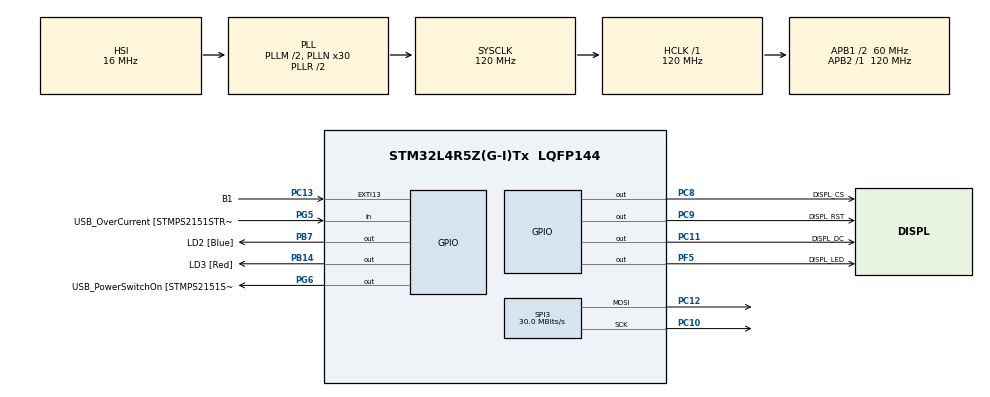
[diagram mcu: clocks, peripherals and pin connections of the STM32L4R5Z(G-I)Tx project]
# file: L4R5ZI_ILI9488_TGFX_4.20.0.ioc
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Dma.Request0=SPI3_TX
Dma.SPI3_TX.0.Direction=DMA_MEMORY_TO_PERIPH
Dma.SPI3_TX.0.EventEnable=DISABLE
Dma.SPI3_TX.0.Instance=DMA1_Channel1
Dma.SPI3_TX.0.MemDataAlignment=DMA_MDATAALIGN_BYTE
Dma.SPI3_TX.0.MemInc=DMA_MINC_ENABLE
Dma.SPI3_TX.0.Mode=DMA_NORMAL
Dma.SPI3_TX.0.PeriphDataAlignment=DMA_PDATAALIGN_BYTE
Dma.SPI3_TX.0.PeriphInc=DMA_PINC_DISABLE
Dma.SPI3_TX.0.Polarity=HAL_DMAMUX_REQUEST_GEN_RISING
Dma.SPI3_TX.0.Priority=DMA_PRIORITY_LOW
Dma.SPI3_TX.0.RequestNumber=1
Dma.SPI3_TX.0.SignalID=NONE
Dma.SPI3_TX.0.SyncEnable=DISABLE
Dma.SPI3_TX.0.SyncPolarity=HAL_DMAMUX_SYNC_NO_EVENT
Dma.SPI3_TX.0.SyncRequestNumber=1
Dma.SPI3_TX.0.SyncSignalID=NONE
Mcu.Family=STM32L4
Mcu.Name=STM32L4R5Z(G-I)Tx
Mcu.Package=LQFP144
NVIC.DMA1_Channel1_IRQn=true\:0\:0\:false\:false\:true\:false\:true\:true
NVIC.PriorityGroup=NVIC_PRIORITYGROUP_4
NVIC.SPI3_IRQn=true\:0\:0\:false\:false\:true\:true\:true\:true
NVIC.TIM3_IRQn=true\:0\:0\:false\:false\:true\:true\:true\:true
PA10.GPIO_Label=USB_ID
PA10.Signal=USB_OTG_FS_ID
PA11.GPIO_Label=USB_DM
PA11.Signal=USB_OTG_FS_DM
PA12.GPIO_Label=USB_DP
PA12.Signal=USB_OTG_FS_DP
PA13\ (JTMS/SWDIO).GPIO_Label=TMS
PA13\ (JTMS/SWDIO).Mode=Trace_Asynchronous_SW
PA13\ (JTMS/SWDIO).Signal=SYS_JTMS-SWDIO
PA14\ (JTCK/SWCLK).GPIO_Label=TCK
PA14\ (JTCK/SWCLK).Mode=Trace_Asynchronous_SW
PA14\ (JTCK/SWCLK).Signal=SYS_JTCK-SWCLK
PA8.GPIO_Label=USB_SOF [TP1]
PA8.Signal=USB_OTG_FS_SOF
PA9.GPIO_Label=USB_VBUS
PA9.Signal=USB_OTG_FS_VBUS
PB14.GPIO_Label=LD3 [Red]
PB14.Signal=GPIO_Output
PB3\ (JTDO/TRACESWO).GPIO_Label=SWO
PB3\ (JTDO/TRACESWO).Mode=Trace_Asynchronous_SW
PB3\ (JTDO/TRACESWO).Signal=SYS_JTDO-SWO
PB7.GPIO_Label=LD2 [Blue]
PB7.Signal=GPIO_Output
PC10.Mode=TX_Only_Simplex_Unidirect_Master
PC10.Signal=SPI3_SCK
PC11.GPIO_Label=DISPL_DC
PC11.GPIO_Speed=GPIO_SPEED_FREQ_HIGH
PC11.Signal=GPIO_Output
PC12.Mode=TX_Only_Simplex_Unidirect_Master
PC12.Signal=SPI3_MOSI
PC13.GPIO_Label=B1
PC13.Signal=GPXTI13
PC14-OSC32_IN\ (PC14).Mode=LSE-External-Oscillator
PC14-OSC32_IN\ (PC14).Signal=RCC_OSC32_IN
PC15-OSC32_OUT\ (PC15).Mode=LSE-External-Oscillator
PC15-OSC32_OUT\ (PC15).Signal=RCC_OSC32_OUT
PC8.GPIO_Label=DISPL_CS
PC8.GPIO_Speed=GPIO_SPEED_FREQ_HIGH
PC8.Signal=GPIO_Output
PC9.GPIO_Label=DISPL_RST
PC9.GPIO_Speed=GPIO_SPEED_FREQ_HIGH
PC9.Signal=GPIO_Output
PD8.GPIO_Label=STLK_RX [STM32F103CBT6_PA3]
PD8.Signal=USART3_TX
PD9.GPIO_Label=STLK_TX [STM32F103CBT6_PA2]
PD9.Signal=USART3_RX
PF5.GPIO_Label=DISPL_LED
PF5.Signal=GPIO_Output
PG5.GPIO_Label=USB_OverCurrent [STMPS2151STR_FAULT]
PG5.Signal=GPIO_Input
PG6.GPIO_Label=USB_PowerSwitchOn [STMPS2151STR_EN]
PG6.Signal=GPIO_Output
PG7.GPIO_Label=STLINK_TX
PG7.Signal=LPUART1_TX
PG8.GPIO_Label=STLINK_RX
PG8.Signal=LPUART1_RX
PH0-OSC_IN\ (PH0).Signal=RCC_OSC_IN
PH1-OSC_OUT\ (PH1).Signal=RCC_OSC_OUT
ProjectManager.HeapSize=0x200
ProjectManager.StackSize=0x400
ProjectManager.TargetToolchain=STM32CubeIDE
RCC.48MHZClocksFreq_Value=24000000
RCC.ADCFreq_Value=96000000
RCC.AHBFreq_Value=120000000
RCC.APB1CLKDivider=RCC_HCLK_DIV2
RCC.APB1Freq_Value=60000000
RCC.APB1TimFreq_Value=120000000
RCC.APB2Freq_Value=120000000
RCC.APB2TimFreq_Value=120000000
RCC.CK48CLockSelection=RCC_USBCLKSOURCE_HSI48
RCC.CortexFreq_Value=120000000
RCC.HCLKFreq_Value=120000000
RCC.HSE_VALUE=8000000
RCC.HSI48_VALUE=48000000
RCC.HSI_VALUE=16000000
RCC.MSI_VALUE=4000000
RCC.PLLM1=2
RCC.PLLMUL=RCC_PLL_MUL9
RCC.PLLN=30
RCC.PLLSAI1N=12
RCC.PLLSourceVirtual=RCC_PLLSOURCE_HSI
RCC.PRESCALERUSB=RCC_USBCLKSOURCE_PLL_DIV1_5
RCC.SYSCLKFreq_VALUE=120000000
RCC.SYSCLKSource=RCC_SYSCLKSOURCE_PLLCLK
RCC.SYSCLKSourceVirtual=RCC_SYSCLKSOURCE_PLLCLK
RCC.USBFreq_Value=48000000
RCC.VCOOutputFreq_Value=240000000
SPI3.BaudRatePrescaler=SPI_BAUDRATEPRESCALER_2
SPI3.CalculateBaudRate=30.0 MBits/s
SPI3.DataSize=SPI_DATASIZE_8BIT
SPI3.Direction=SPI_DIRECTION_2LINES
SPI3.Mode=SPI_MODE_MASTER
SPI3.VirtualType=VM_MASTER
STMicroelectronics.X-CUBE-TOUCHGFX.4.20.0.ApplicationCcGraphicsJjApplication=TouchGFXOoGenerator
STMicroelectronics.X-CUBE-TOUCHGFX.4.20.0.tgfx_block_size=27648
STMicroelectronics.X-CUBE-TOUCHGFX.4.20.0.tgfx_buffering_strategy=Partial
STMicroelectronics.X-CUBE-TOUCHGFX.4.20.0.tgfx_custom_height=480
STMicroelectronics.X-CUBE-TOUCHGFX.4.20.0.tgfx_custom_width=320
STMicroelectronics.X-CUBE-TOUCHGFX.4.20.0_IsPackSelfContextualization=true
TIM3.Period=50000-1
TIM3.Prescaler=120-1
VP_CRC_VS_CRC.Mode=CRC_Activate
VP_STMicroelectronics.X-CUBE-TOUCHGFX_VS_GraphicsJjApplication_4.20.0.Mode=GraphicsJjApplication
VP_TIM3_VS_ClockSourceINT.Mode=Internal
board=NUCLEO-L4R5ZI

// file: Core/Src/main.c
/* USER CODE BEGIN Header */
/**
  ******************************************************************************
  * @file           : main.c
  * @brief          : Main program body
  ******************************************************************************
  * @attention
  *
  * Copyright (c) 2024 STMicroelectronics.
  * All rights reserved.
  *
  * This software is licensed under terms that can be found in the LICENSE file
  * in the root directory of this software component.
  * If no LICENSE file comes with this software, it is provided AS-IS.
  *
  ******************************************************************************
  */
/* USER CODE END Header */
#include "main.h"
#include "app_touchgfx.h"

CRC_HandleTypeDef hcrc;

SPI_HandleTypeDef hspi3;
DMA_HandleTypeDef hdma_spi3_tx;

TIM_HandleTypeDef htim3;

void SystemClock_Config(void);
static void MX_GPIO_Init(void);
static void MX_DMA_Init(void);
static void MX_TIM3_Init(void);
static void MX_SPI3_Init(void);
static void MX_CRC_Init(void);

int main(void)
{

  /* MCU Configuration--------------------------------------------------------*/

  /* Reset of all peripherals, Initializes the Flash interface and the Systick. */
  HAL_Init();

  /* Configure the system clock */
  SystemClock_Config();

  /* Initialize all configured peripherals */
  MX_GPIO_Init();
  MX_DMA_Init();
  MX_TIM3_Init();
  MX_SPI3_Init();
  MX_CRC_Init();
  MX_TouchGFX_Init();
  /* USER CODE BEGIN 2 */
  if(HAL_TIM_Base_Start_IT(&htim3) != HAL_OK)
  {
	  Error_Handler();
  }
  MX_TouchGFX_Init();
  Displ_Init(Displ_Orientat_0);
  //Displ_CLS(BLACK);
  Displ_BackLight('1');
  /* USER CODE END 2 */

  /* Infinite loop */
  while (1)
  {

  MX_TouchGFX_Process();
    /* USER CODE BEGIN 3 */
	  //Displ_PerfTest();
  }
  /* USER CODE END 3 */
}

void SystemClock_Config(void)
{
  RCC_OscInitTypeDef RCC_OscInitStruct = {0};
  RCC_ClkInitTypeDef RCC_ClkInitStruct = {0};

  /** Configure the main internal regulator output voltage
  */
  if (HAL_PWREx_ControlVoltageScaling(PWR_REGULATOR_VOLTAGE_SCALE1_BOOST) != HAL_OK)
  {
    Error_Handler();
  }

  /** Initializes the RCC Oscillators according to the specified parameters
  * in the RCC_OscInitTypeDef structure.
  */
  RCC_OscInitStruct.OscillatorType = RCC_OSCILLATORTYPE_HSI;
  RCC_OscInitStruct.HSIState = RCC_HSI_ON;
  RCC_OscInitStruct.HSICalibrationValue = RCC_HSICALIBRATION_DEFAULT;
  RCC_OscInitStruct.PLL.PLLState = RCC_PLL_ON;
  RCC_OscInitStruct.PLL.PLLSource = RCC_PLLSOURCE_HSI;
  RCC_OscInitStruct.PLL.PLLM = 2;
  RCC_OscInitStruct.PLL.PLLN = 30;
  RCC_OscInitStruct.PLL.PLLP = RCC_PLLP_DIV2;
  RCC_OscInitStruct.PLL.PLLQ = RCC_PLLQ_DIV2;
  RCC_OscInitStruct.PLL.PLLR = RCC_PLLR_DIV2;
  if (HAL_RCC_OscConfig(&RCC_OscInitStruct) != HAL_OK)
  {
    Error_Handler();
  }

  /** Initializes the CPU, AHB and APB buses clocks
  */
  RCC_ClkInitStruct.ClockType = RCC_CLOCKTYPE_HCLK|RCC_CLOCKTYPE_SYSCLK
                              |RCC_CLOCKTYPE_PCLK1|RCC_CLOCKTYPE_PCLK2;
  RCC_ClkInitStruct.SYSCLKSource = RCC_SYSCLKSOURCE_PLLCLK;
  RCC_ClkInitStruct.AHBCLKDivider = RCC_SYSCLK_DIV1;
  RCC_ClkInitStruct.APB1CLKDivider = RCC_HCLK_DIV2;
  RCC_ClkInitStruct.APB2CLKDivider = RCC_HCLK_DIV1;

  if (HAL_RCC_ClockConfig(&RCC_ClkInitStruct, FLASH_LATENCY_5) != HAL_OK)
  {
    Error_Handler();
  }
}

static void MX_CRC_Init(void)
{

  hcrc.Instance = CRC;
  hcrc.Init.DefaultPolynomialUse = DEFAULT_POLYNOMIAL_ENABLE;
  hcrc.Init.DefaultInitValueUse = DEFAULT_INIT_VALUE_ENABLE;
  hcrc.Init.InputDataInversionMode = CRC_INPUTDATA_INVERSION_NONE;
  hcrc.Init.OutputDataInversionMode = CRC_OUTPUTDATA_INVERSION_DISABLE;
  hcrc.InputDataFormat = CRC_INPUTDATA_FORMAT_BYTES;
  if (HAL_CRC_Init(&hcrc) != HAL_OK)
  {
    Error_Handler();
  }

}

static void MX_SPI3_Init(void)
{

  /* SPI3 parameter configuration*/
  hspi3.Instance = SPI3;
  hspi3.Init.Mode = SPI_MODE_MASTER;
  hspi3.Init.Direction = SPI_DIRECTION_2LINES;
  hspi3.Init.DataSize = SPI_DATASIZE_8BIT;
  hspi3.Init.CLKPolarity = SPI_POLARITY_LOW;
  hspi3.Init.CLKPhase = SPI_PHASE_1EDGE;
  hspi3.Init.NSS = SPI_NSS_SOFT;
  hspi3.Init.BaudRatePrescaler = SPI_BAUDRATEPRESCALER_2;
  hspi3.Init.FirstBit = SPI_FIRSTBIT_MSB;
  hspi3.Init.TIMode = SPI_TIMODE_DISABLE;
  hspi3.Init.CRCCalculation = SPI_CRCCALCULATION_DISABLE;
  hspi3.Init.CRCPolynomial = 7;
  hspi3.Init.CRCLength = SPI_CRC_LENGTH_DATASIZE;
  hspi3.Init.NSSPMode = SPI_NSS_PULSE_ENABLE;
  if (HAL_SPI_Init(&hspi3) != HAL_OK)
  {
    Error_Handler();
  }

}

static void MX_TIM3_Init(void)
{

  TIM_ClockConfigTypeDef sClockSourceConfig = {0};
  TIM_MasterConfigTypeDef sMasterConfig = {0};

  htim3.Instance = TIM3;
  htim3.Init.Prescaler = 120-1;
  htim3.Init.CounterMode = TIM_COUNTERMODE_UP;
  htim3.Init.Period = 50000-1;
  htim3.Init.ClockDivision = TIM_CLOCKDIVISION_DIV1;
  htim3.Init.AutoReloadPreload = TIM_AUTORELOAD_PRELOAD_DISABLE;
  if (HAL_TIM_Base_Init(&htim3) != HAL_OK)
  {
    Error_Handler();
  }
  sClockSourceConfig.ClockSource = TIM_CLOCKSOURCE_INTERNAL;
  if (HAL_TIM_ConfigClockSource(&htim3, &sClockSourceConfig) != HAL_OK)
  {
    Error_Handler();
  }
  sMasterConfig.MasterOutputTrigger = TIM_TRGO_RESET;
  sMasterConfig.MasterSlaveMode = TIM_MASTERSLAVEMODE_DISABLE;
  if (HAL_TIMEx_MasterConfigSynchronization(&htim3, &sMasterConfig) != HAL_OK)
  {
    Error_Handler();
  }

}

static void MX_DMA_Init(void)
{

  /* DMA controller clock enable */
  __HAL_RCC_DMAMUX1_CLK_ENABLE();
  __HAL_RCC_DMA1_CLK_ENABLE();

  /* DMA interrupt init */
  /* DMA1_Channel1_IRQn interrupt configuration */
  HAL_NVIC_SetPriority(DMA1_Channel1_IRQn, 0, 0);
  HAL_NVIC_EnableIRQ(DMA1_Channel1_IRQn);
  /* DMAMUX1_OVR_IRQn interrupt configuration */
  HAL_NVIC_SetPriority(DMAMUX1_OVR_IRQn, 0, 0);
  HAL_NVIC_EnableIRQ(DMAMUX1_OVR_IRQn);

}

static void MX_GPIO_Init(void)
{
  GPIO_InitTypeDef GPIO_InitStruct = {0};

  /* GPIO Ports Clock Enable */
  __HAL_RCC_GPIOC_CLK_ENABLE();
  __HAL_RCC_GPIOF_CLK_ENABLE();
  __HAL_RCC_GPIOH_CLK_ENABLE();
  __HAL_RCC_GPIOB_CLK_ENABLE();
  __HAL_RCC_GPIOD_CLK_ENABLE();
  __HAL_RCC_GPIOG_CLK_ENABLE();
  HAL_PWREx_EnableVddIO2();
  __HAL_RCC_GPIOA_CLK_ENABLE();

  /*Configure GPIO pin Output Level */
  HAL_GPIO_WritePin(DISPL_LED_GPIO_Port, DISPL_LED_Pin, GPIO_PIN_RESET);

  /*Configure GPIO pin Output Level */
  HAL_GPIO_WritePin(GPIOB, LD3_Pin|LD2_Pin, GPIO_PIN_RESET);

  /*Configure GPIO pin Output Level */
  HAL_GPIO_WritePin(USB_PowerSwitchOn_GPIO_Port, USB_PowerSwitchOn_Pin, GPIO_PIN_RESET);

  /*Configure GPIO pin Output Level */
  HAL_GPIO_WritePin(GPIOC, DISPL_CS_Pin|DISPL_RST_Pin|DISPL_DC_Pin, GPIO_PIN_RESET);

  /*Configure GPIO pin : B1_Pin */
  GPIO_InitStruct.Pin = B1_Pin;
  GPIO_InitStruct.Mode = GPIO_MODE_IT_RISING;
  GPIO_InitStruct.Pull = GPIO_NOPULL;
  HAL_GPIO_Init(B1_GPIO_Port, &GPIO_InitStruct);

  /*Configure GPIO pin : DISPL_LED_Pin */
  GPIO_InitStruct.Pin = DISPL_LED_Pin;
  GPIO_InitStruct.Mode = GPIO_MODE_OUTPUT_PP;
  GPIO_InitStruct.Pull = GPIO_NOPULL;
  GPIO_InitStruct.Speed = GPIO_SPEED_FREQ_LOW;
  HAL_GPIO_Init(DISPL_LED_GPIO_Port, &GPIO_InitStruct);

  /*Configure GPIO pins : LD3_Pin LD2_Pin */
  GPIO_InitStruct.Pin = LD3_Pin|LD2_Pin;
  GPIO_InitStruct.Mode = GPIO_MODE_OUTPUT_PP;
  GPIO_InitStruct.Pull = GPIO_NOPULL;
  GPIO_InitStruct.Speed = GPIO_SPEED_FREQ_LOW;
  HAL_GPIO_Init(GPIOB, &GPIO_InitStruct);

  /*Configure GPIO pins : STLK_RX_Pin STLK_TX_Pin */
  GPIO_InitStruct.Pin = STLK_RX_Pin|STLK_TX_Pin;
  GPIO_InitStruct.Mode = GPIO_MODE_AF_PP;
  GPIO_InitStruct.Pull = GPIO_NOPULL;
  GPIO_InitStruct.Speed = GPIO_SPEED_FREQ_VERY_HIGH;
  GPIO_InitStruct.Alternate = GPIO_AF7_USART3;
  HAL_GPIO_Init(GPIOD, &GPIO_InitStruct);

  /*Configure GPIO pin : USB_OverCurrent_Pin */
  GPIO_InitStruct.Pin = USB_OverCurrent_Pin;
  GPIO_InitStruct.Mode = GPIO_MODE_INPUT;
  GPIO_InitStruct.Pull = GPIO_NOPULL;
  HAL_GPIO_Init(USB_OverCurrent_GPIO_Port, &GPIO_InitStruct);

  /*Configure GPIO pin : USB_PowerSwitchOn_Pin */
  GPIO_InitStruct.Pin = USB_PowerSwitchOn_Pin;
  GPIO_InitStruct.Mode = GPIO_MODE_OUTPUT_PP;
  GPIO_InitStruct.Pull = GPIO_NOPULL;
  GPIO_InitStruct.Speed = GPIO_SPEED_FREQ_LOW;
  HAL_GPIO_Init(USB_PowerSwitchOn_GPIO_Port, &GPIO_InitStruct);

  /*Configure GPIO pins : STLINK_TX_Pin STLINK_RX_Pin */
  GPIO_InitStruct.Pin = STLINK_TX_Pin|STLINK_RX_Pin;
  GPIO_InitStruct.Mode = GPIO_MODE_AF_PP;
  GPIO_InitStruct.Pull = GPIO_NOPULL;
  GPIO_InitStruct.Speed = GPIO_SPEED_FREQ_VERY_HIGH;
  GPIO_InitStruct.Alternate = GPIO_AF8_LPUART1;
  HAL_GPIO_Init(GPIOG, &GPIO_InitStruct);

  /*Configure GPIO pins : DISPL_CS_Pin DISPL_RST_Pin DISPL_DC_Pin */
  GPIO_InitStruct.Pin = DISPL_CS_Pin|DISPL_RST_Pin|DISPL_DC_Pin;
  GPIO_InitStruct.Mode = GPIO_MODE_OUTPUT_PP;
  GPIO_InitStruct.Pull = GPIO_NOPULL;
  GPIO_InitStruct.Speed = GPIO_SPEED_FREQ_HIGH;
  HAL_GPIO_Init(GPIOC, &GPIO_InitStruct);

  /*Configure GPIO pins : USB_SOF_Pin USB_ID_Pin USB_DM_Pin USB_DP_Pin */
  GPIO_InitStruct.Pin = USB_SOF_Pin|USB_ID_Pin|USB_DM_Pin|USB_DP_Pin;
  GPIO_InitStruct.Mode = GPIO_MODE_AF_PP;
  GPIO_InitStruct.Pull = GPIO_NOPULL;
  GPIO_InitStruct.Speed = GPIO_SPEED_FREQ_VERY_HIGH;
  GPIO_InitStruct.Alternate = GPIO_AF10_OTG_FS;
  HAL_GPIO_Init(GPIOA, &GPIO_InitStruct);

  /*Configure GPIO pin : USB_VBUS_Pin */
  GPIO_InitStruct.Pin = USB_VBUS_Pin;
  GPIO_InitStruct.Mode = GPIO_MODE_INPUT;
  GPIO_InitStruct.Pull = GPIO_NOPULL;
  HAL_GPIO_Init(USB_VBUS_GPIO_Port, &GPIO_InitStruct);

}

/* USER CODE BEGIN 4 */
void HAL_TIM_PeriodElapsedCallback(TIM_HandleTypeDef *htim)
{
	HAL_GPIO_TogglePin(LD2_GPIO_Port, LD2_Pin);
	touchgfxSignalVSync();
}
/* USER CODE END 4 */

void Error_Handler(void)
{
  __disable_irq();
  while (1)
  {
  }
}
